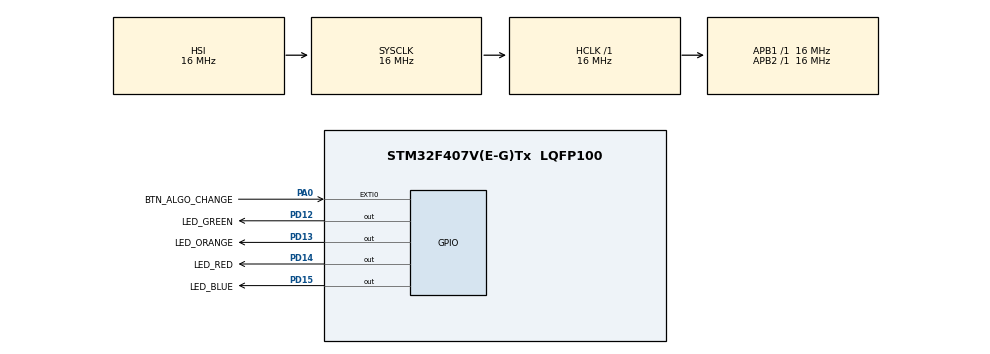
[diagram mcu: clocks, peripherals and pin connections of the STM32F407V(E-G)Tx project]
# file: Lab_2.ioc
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Mcu.Family=STM32F4
Mcu.Name=STM32F407V(E-G)Tx
Mcu.Package=LQFP100
NVIC.EXTI0_IRQn=true\:0\:0\:false\:false\:true\:true\:true\:true
NVIC.PriorityGroup=NVIC_PRIORITYGROUP_4
PA0-WKUP.GPIO_Label=BTN_ALGO_CHANGE
PA0-WKUP.Signal=GPXTI0
PD12.GPIO_Label=LED_GREEN
PD12.Signal=GPIO_Output
PD13.GPIO_Label=LED_ORANGE
PD13.Signal=GPIO_Output
PD14.GPIO_Label=LED_RED
PD14.Signal=GPIO_Output
PD15.GPIO_Label=LED_BLUE
PD15.Signal=GPIO_Output
ProjectManager.HeapSize=0x200
ProjectManager.StackSize=0x400
ProjectManager.TargetToolchain=STM32CubeIDE
RCC.AHBFreq_Value=16000000
RCC.APB1Freq_Value=16000000
RCC.APB2Freq_Value=16000000
RCC.CortexFreq_Value=16000000
RCC.HSE_VALUE=25000000
RCC.HSI_VALUE=16000000
RCC.LSE_VALUE=32768
RCC.SYSCLKFreq_VALUE=16000000
RCC.VCOOutputFreq_Value=192000000
board=custom

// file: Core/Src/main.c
/* USER CODE BEGIN Header */
/**
  ******************************************************************************
  * @file           : main.c
  * @brief          : Main program body
  ******************************************************************************
  * @attention
  *
  * Copyright (c) 2025 STMicroelectronics.
  * All rights reserved.
  *
  * This software is licensed under terms that can be found in the LICENSE file
  * in the root directory of this software component.
  * If no LICENSE file comes with this software, it is provided AS-IS.
  *
  ******************************************************************************
  */
/* USER CODE END Header */
#include "main.h"

/* USER CODE BEGIN Includes */
#include <math.h>
#include <stdbool.h>
/* USER CODE END Includes */

/* USER CODE BEGIN PD */
#define LED_SWITCH_DELAY	(500)
/* USER CODE END PD */

/* USER CODE BEGIN PV */
unsigned int algo_num = 0;
bool exit_loop = false;
/* USER CODE END PV */

void SystemClock_Config(void);
static void MX_GPIO_Init(void);

int main(void)
{

  /* MCU Configuration--------------------------------------------------------*/

  /* Reset of all peripherals, Initializes the Flash interface and the Systick. */
  HAL_Init();

  /* Configure the system clock */
  SystemClock_Config();

  /* Initialize all configured peripherals */
  MX_GPIO_Init();

  /* Infinite loop */
  while (1)
  {

	  if (algo_num == 0) {
		  HAL_GPIO_WritePin(LED_GREEN_GPIO_Port, LED_GREEN_Pin, GPIO_PIN_RESET);
		  HAL_GPIO_WritePin(LED_ORANGE_GPIO_Port, LED_ORANGE_Pin, GPIO_PIN_SET);
		  HAL_GPIO_WritePin(LED_RED_GPIO_Port, LED_RED_Pin, GPIO_PIN_SET);
		  HAL_GPIO_WritePin(LED_BLUE_GPIO_Port, LED_BLUE_Pin, GPIO_PIN_SET);
		  HAL_Delay(LED_SWITCH_DELAY);

		  HAL_GPIO_WritePin(LED_ORANGE_GPIO_Port, LED_ORANGE_Pin, GPIO_PIN_RESET);
		  HAL_GPIO_WritePin(LED_GREEN_GPIO_Port, LED_GREEN_Pin, GPIO_PIN_SET);
		  HAL_Delay(LED_SWITCH_DELAY);

		  HAL_GPIO_WritePin(LED_RED_GPIO_Port, LED_RED_Pin, GPIO_PIN_RESET);
		  HAL_GPIO_WritePin(LED_ORANGE_GPIO_Port, LED_ORANGE_Pin, GPIO_PIN_SET);
		  HAL_Delay(LED_SWITCH_DELAY);

		  HAL_GPIO_WritePin(LED_BLUE_GPIO_Port, LED_BLUE_Pin, GPIO_PIN_RESET);
		  HAL_GPIO_WritePin(LED_RED_GPIO_Port, LED_RED_Pin, GPIO_PIN_SET);
		  HAL_Delay(LED_SWITCH_DELAY);

	  }
	  else if (algo_num == 1) {
		  exit_loop = false;
		  // binary 0-15 count
		  int bits[] = {0, 0, 0, 0}; // green, orange, red, blue LED ("little-endian")
		  for (int i = 0; i < 16; i++) {
			  if (exit_loop) {
				  HAL_GPIO_WritePin(LED_GREEN_GPIO_Port, LED_GREEN_Pin, GPIO_PIN_RESET);
				  HAL_GPIO_WritePin(LED_ORANGE_GPIO_Port, LED_ORANGE_Pin, GPIO_PIN_RESET);
				  HAL_GPIO_WritePin(LED_RED_GPIO_Port, LED_RED_Pin, GPIO_PIN_RESET);
				  HAL_GPIO_WritePin(LED_BLUE_GPIO_Port, LED_BLUE_Pin, GPIO_PIN_RESET);
				  break;
			  }
			  // converting decimal to binary
			  bits[0] = (i % (int)(pow(2, 1)) == 1) ? 1 : 0; 									// = 1: 1, 3, 5, 7, 9, 11, 13, 15
			  bits[1] = (1 < (i % (int)(pow(2, 2))) && (i % (int)(pow(2, 2))) < 4) ? 1 : 0; 	// = 1: 2, 3, 6, 7, 10, 11, 14, 15
			  bits[2] = (3 < (i % (int)(pow(2, 3))) && (i % (int)(pow(2, 3))) < 8) ? 1 : 0; 	// = 1: 4, 5, 6, 7, 12, 13, 14, 15
			  bits[3] = (7 < (i % (int)(pow(2, 4))) && (i % (int)(pow(2, 3))) < 16) ? 1 : 0; 	// = 1: 8, 9, 10, 11, 12, 13, 14, 15

			  // binary number display
			  (bits[0] == 1) ?
					  HAL_GPIO_WritePin(LED_GREEN_GPIO_Port, LED_GREEN_Pin, GPIO_PIN_SET) :
					  HAL_GPIO_WritePin(LED_GREEN_GPIO_Port, LED_GREEN_Pin, GPIO_PIN_RESET);
			  (bits[1] == 1) ?
					  HAL_GPIO_WritePin(LED_ORANGE_GPIO_Port, LED_ORANGE_Pin, GPIO_PIN_SET) :
					  HAL_GPIO_WritePin(LED_ORANGE_GPIO_Port, LED_ORANGE_Pin, GPIO_PIN_RESET);
			  (bits[2] == 1) ?
					  HAL_GPIO_WritePin(LED_RED_GPIO_Port, LED_RED_Pin, GPIO_PIN_SET) :
					  HAL_GPIO_WritePin(LED_RED_GPIO_Port, LED_RED_Pin, GPIO_PIN_RESET);
			  (bits[3] == 1) ?
					  HAL_GPIO_WritePin(LED_BLUE_GPIO_Port, LED_BLUE_Pin, GPIO_PIN_SET) :
					  HAL_GPIO_WritePin(LED_BLUE_GPIO_Port, LED_BLUE_Pin, GPIO_PIN_RESET);

			  HAL_Delay(LED_SWITCH_DELAY);
		  }

	  }
	  else if (algo_num == 2) {
		  HAL_GPIO_WritePin(LED_GREEN_GPIO_Port, LED_GREEN_Pin, GPIO_PIN_SET);
		  HAL_GPIO_WritePin(LED_ORANGE_GPIO_Port, LED_ORANGE_Pin, GPIO_PIN_RESET);
		  HAL_GPIO_WritePin(LED_RED_GPIO_Port, LED_RED_Pin, GPIO_PIN_SET);
		  HAL_GPIO_WritePin(LED_BLUE_GPIO_Port, LED_BLUE_Pin, GPIO_PIN_RESET);
		  HAL_Delay(LED_SWITCH_DELAY);

		  HAL_GPIO_WritePin(LED_GREEN_GPIO_Port, LED_GREEN_Pin, GPIO_PIN_RESET);
		  HAL_GPIO_WritePin(LED_ORANGE_GPIO_Port, LED_ORANGE_Pin, GPIO_PIN_SET);
		  HAL_GPIO_WritePin(LED_RED_GPIO_Port, LED_RED_Pin, GPIO_PIN_RESET);
		  HAL_GPIO_WritePin(LED_BLUE_GPIO_Port, LED_BLUE_Pin, GPIO_PIN_SET);
		  HAL_Delay(LED_SWITCH_DELAY);

		  HAL_GPIO_WritePin(LED_GREEN_GPIO_Port, LED_GREEN_Pin|LED_ORANGE_Pin|LED_RED_Pin|LED_BLUE_Pin, GPIO_PIN_RESET);
	  }
	  else {
		  HAL_GPIO_WritePin(LED_RED_GPIO_Port, LED_RED_Pin, GPIO_PIN_SET);
		  HAL_Delay(LED_SWITCH_DELAY / 50 * 5); // led / 50 * 1 = 10 ms
		  HAL_GPIO_WritePin(LED_RED_GPIO_Port, LED_RED_Pin, GPIO_PIN_RESET);
		  HAL_Delay(LED_SWITCH_DELAY / 50 * 4);

		  HAL_GPIO_WritePin(LED_GREEN_GPIO_Port, LED_GREEN_Pin, GPIO_PIN_SET);
		  HAL_Delay(LED_SWITCH_DELAY / 50 * 5);
		  HAL_GPIO_WritePin(LED_GREEN_GPIO_Port, LED_GREEN_Pin, GPIO_PIN_RESET);
		  HAL_Delay(LED_SWITCH_DELAY / 50 * 4);

		  HAL_GPIO_WritePin(LED_RED_GPIO_Port, LED_RED_Pin, GPIO_PIN_SET);
		  HAL_Delay(LED_SWITCH_DELAY / 50 * 5);
		  HAL_GPIO_WritePin(LED_RED_GPIO_Port, LED_RED_Pin, GPIO_PIN_RESET);
		  HAL_Delay(LED_SWITCH_DELAY / 50 * 15);

		  HAL_GPIO_WritePin(LED_GREEN_GPIO_Port, LED_GREEN_Pin, GPIO_PIN_SET);
		  HAL_Delay(LED_SWITCH_DELAY / 50 * 5);
		  HAL_GPIO_WritePin(LED_GREEN_GPIO_Port, LED_GREEN_Pin, GPIO_PIN_RESET);
		  HAL_Delay(LED_SWITCH_DELAY / 50 * 15);

		  HAL_GPIO_WritePin(LED_ORANGE_GPIO_Port, LED_ORANGE_Pin, GPIO_PIN_SET);
		  HAL_Delay(LED_SWITCH_DELAY / 50 * 5); // led / 50 * 1 = 10 ms
		  HAL_GPIO_WritePin(LED_ORANGE_GPIO_Port, LED_ORANGE_Pin, GPIO_PIN_RESET);
		  HAL_Delay(LED_SWITCH_DELAY / 50 * 4);

		  HAL_GPIO_WritePin(LED_BLUE_GPIO_Port, LED_BLUE_Pin, GPIO_PIN_SET);
		  HAL_Delay(LED_SWITCH_DELAY / 50 * 5);
		  HAL_GPIO_WritePin(LED_BLUE_GPIO_Port, LED_BLUE_Pin, GPIO_PIN_RESET);
		  HAL_Delay(LED_SWITCH_DELAY / 50 * 4);

		  HAL_GPIO_WritePin(LED_ORANGE_GPIO_Port, LED_ORANGE_Pin, GPIO_PIN_SET);
		  HAL_Delay(LED_SWITCH_DELAY / 50 * 5);
		  HAL_GPIO_WritePin(LED_ORANGE_GPIO_Port, LED_ORANGE_Pin, GPIO_PIN_RESET);
		  HAL_Delay(LED_SWITCH_DELAY / 50 * 15);

		  HAL_GPIO_WritePin(LED_BLUE_GPIO_Port, LED_BLUE_Pin, GPIO_PIN_SET);
		  HAL_Delay(LED_SWITCH_DELAY / 50 * 5);
		  HAL_GPIO_WritePin(LED_BLUE_GPIO_Port, LED_BLUE_Pin, GPIO_PIN_RESET);
		  HAL_Delay(LED_SWITCH_DELAY / 50 * 15);
	  }

  }
}

void SystemClock_Config(void)
{
  RCC_OscInitTypeDef RCC_OscInitStruct = {0};
  RCC_ClkInitTypeDef RCC_ClkInitStruct = {0};

  /** Configure the main internal regulator output voltage
  */
  __HAL_RCC_PWR_CLK_ENABLE();
  __HAL_PWR_VOLTAGESCALING_CONFIG(PWR_REGULATOR_VOLTAGE_SCALE1);

  /** Initializes the RCC Oscillators according to the specified parameters
  * in the RCC_OscInitTypeDef structure.
  */
  RCC_OscInitStruct.OscillatorType = RCC_OSCILLATORTYPE_HSI;
  RCC_OscInitStruct.HSIState = RCC_HSI_ON;
  RCC_OscInitStruct.HSICalibrationValue = RCC_HSICALIBRATION_DEFAULT;
  RCC_OscInitStruct.PLL.PLLState = RCC_PLL_NONE;
  if (HAL_RCC_OscConfig(&RCC_OscInitStruct) != HAL_OK)
  {
    Error_Handler();
  }

  /** Initializes the CPU, AHB and APB buses clocks
  */
  RCC_ClkInitStruct.ClockType = RCC_CLOCKTYPE_HCLK|RCC_CLOCKTYPE_SYSCLK
                              |RCC_CLOCKTYPE_PCLK1|RCC_CLOCKTYPE_PCLK2;
  RCC_ClkInitStruct.SYSCLKSource = RCC_SYSCLKSOURCE_HSI;
  RCC_ClkInitStruct.AHBCLKDivider = RCC_SYSCLK_DIV1;
  RCC_ClkInitStruct.APB1CLKDivider = RCC_HCLK_DIV1;
  RCC_ClkInitStruct.APB2CLKDivider = RCC_HCLK_DIV1;

  if (HAL_RCC_ClockConfig(&RCC_ClkInitStruct, FLASH_LATENCY_0) != HAL_OK)
  {
    Error_Handler();
  }
}

static void MX_GPIO_Init(void)
{
  GPIO_InitTypeDef GPIO_InitStruct = {0};

  /* GPIO Ports Clock Enable */
  __HAL_RCC_GPIOA_CLK_ENABLE();
  __HAL_RCC_GPIOD_CLK_ENABLE();

  /*Configure GPIO pin Output Level */
  HAL_GPIO_WritePin(GPIOD, LED_GREEN_Pin|LED_ORANGE_Pin|LED_RED_Pin|LED_BLUE_Pin, GPIO_PIN_RESET);

  /*Configure GPIO pin : BTN_ALGO_CHANGE_Pin */
  GPIO_InitStruct.Pin = BTN_ALGO_CHANGE_Pin;
  GPIO_InitStruct.Mode = GPIO_MODE_IT_RISING;
  GPIO_InitStruct.Pull = GPIO_NOPULL;
  HAL_GPIO_Init(BTN_ALGO_CHANGE_GPIO_Port, &GPIO_InitStruct);

  /*Configure GPIO pins : LED_GREEN_Pin LED_ORANGE_Pin LED_RED_Pin LED_BLUE_Pin */
  GPIO_InitStruct.Pin = LED_GREEN_Pin|LED_ORANGE_Pin|LED_RED_Pin|LED_BLUE_Pin;
  GPIO_InitStruct.Mode = GPIO_MODE_OUTPUT_PP;
  GPIO_InitStruct.Pull = GPIO_NOPULL;
  GPIO_InitStruct.Speed = GPIO_SPEED_FREQ_LOW;
  HAL_GPIO_Init(GPIOD, &GPIO_InitStruct);

  /* EXTI interrupt init*/
  HAL_NVIC_SetPriority(EXTI0_IRQn, 0, 0);
  HAL_NVIC_EnableIRQ(EXTI0_IRQn);

}

void Error_Handler(void)
{
  __disable_irq();
  while (1)
  {
  }
}
